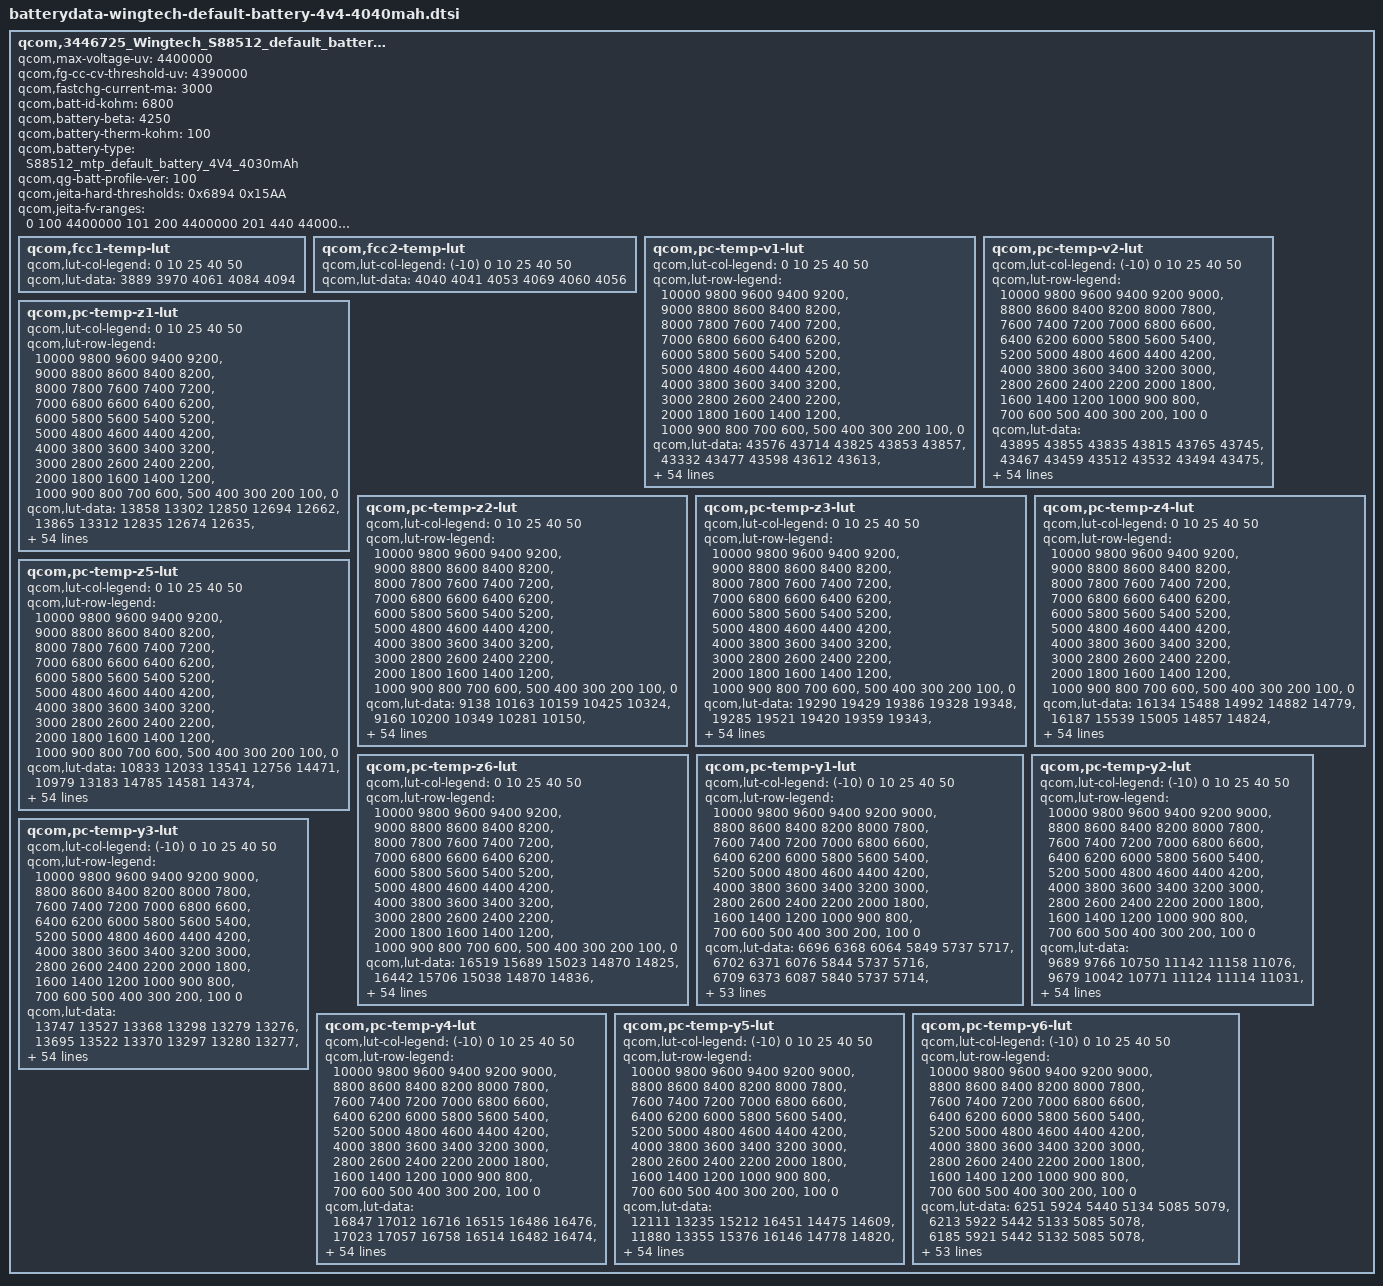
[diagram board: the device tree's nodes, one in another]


qcom,3446725_Wingtech_S88512_default_battery_4V4_4040mAh {
	/* 3446725_Wingtech_S88512_default_battery_4040mAh_averaged_MasterSlave_May16th2018 */
	qcom,max-voltage-uv = <4400000>;
	qcom,fg-cc-cv-threshold-uv = <4390000>;
	qcom,fastchg-current-ma = <3000>;
	qcom,batt-id-kohm = <6800>;
	qcom,battery-beta = <4250>;
	qcom,battery-therm-kohm = <100>;
	qcom,battery-type = "S88512_mtp_default_battery_4V4_4030mAh";
	qcom,qg-batt-profile-ver = <100>;
	/* COLD = 0 DegC, HOT = 60 DegC */
	qcom,jeita-hard-thresholds = <0x6894 0x15AA>;
        qcom,jeita-fv-ranges = <0   100  4400000
                                101 200  4400000
                                201 440  4400000
                                441 580  4100000>;
	qcom,fcc1-temp-lut {
		qcom,lut-col-legend = <0 10 25 40 50>;
		qcom,lut-data = <3889 3970 4061 4084 4094>;
	};

	qcom,fcc2-temp-lut {
		qcom,lut-col-legend = <(-10) 0 10 25 40 50>;
		qcom,lut-data = <4040 4041 4053 4069 4060 4056>;
	};

	qcom,pc-temp-v1-lut {
		qcom,lut-col-legend = <0 10 25 40 50>;
		qcom,lut-row-legend = <10000 9800 9600 9400 9200>,
			<9000 8800 8600 8400 8200>,
			<8000 7800 7600 7400 7200>,
			<7000 6800 6600 6400 6200>,
			<6000 5800 5600 5400 5200>,
			<5000 4800 4600 4400 4200>,
			<4000 3800 3600 3400 3200>,
			<3000 2800 2600 2400 2200>,
			<2000 1800 1600 1400 1200>,
			<1000 900 800 700 600>,
			<500 400 300 200 100>,
			<0>;
		qcom,lut-data = <43576 43714 43825 43853 43857>,
			<43332 43477 43598 43612 43613>,
			<43088 43215 43356 43378 43382>,
			<42842 42957 43107 43140 43149>,
			<42597 42714 42860 42899 42913>,
			<42363 42479 42619 42661 42678>,
			<42137 42254 42382 42425 42443>,
			<41920 42037 42148 42190 42209>,
			<41708 41823 41918 41958 41977>,
			<41506 41604 41694 41728 41746>,
			<41329 41394 41468 41499 41517>,
			<41183 41218 41256 41275 41293>,
			<41009 41069 41079 41067 41073>,
			<40713 40877 40922 40874 40860>,
			<40355 40551 40711 40671 40652>,
			<40111 40219 40387 40436 40450>,
			<39942 40031 40103 40206 40255>,
			<39804 39899 39958 40033 40073>,
			<39684 39779 39848 39888 39901>,
			<39579 39677 39718 39739 39736>,
			<39469 39565 39573 39588 39586>,
			<39357 39368 39405 39420 39426>,
			<39231 39089 39167 39195 39208>,
			<39061 38894 38922 38946 38957>,
			<38861 38779 38769 38774 38778>,
			<38720 38690 38658 38651 38654>,
			<38625 38615 38559 38545 38546>,
			<38553 38553 38464 38445 38443>,
			<38502 38494 38379 38355 38349>,
			<38464 38435 38304 38274 38264>,
			<38427 38382 38239 38201 38189>,
			<38391 38332 38182 38135 38121>,
			<38357 38286 38133 38079 38061>,
			<38321 38246 38090 38027 38005>,
			<38285 38214 38054 37982 37951>,
			<38265 38181 38020 37941 37900>,
			<38259 38150 37985 37896 37846>,
			<38254 38118 37950 37850 37792>,
			<38224 38068 37904 37792 37726>,
			<38131 37977 37825 37710 37639>,
			<38018 37865 37721 37607 37533>,
			<37885 37741 37605 37493 37417>,
			<37732 37596 37469 37360 37286>,
			<37558 37420 37311 37205 37132>,
			<37393 37294 37166 37063 36992>,
			<37277 37208 37071 36976 36917>,
			<37242 37173 37044 36953 36893>,
			<37211 37150 37031 36937 36874>,
			<37183 37124 37015 36920 36859>,
			<37137 37083 36972 36870 36798>,
			<36931 36862 36739 36621 36527>,
			<36489 36423 36306 36187 36086>,
			<35907 35842 35726 35612 35508>,
			<35118 35048 34934 34829 34714>,
			<33872 33805 33702 33622 33487>,
			<30000 30000 30000 30000 30000>;
	};

	qcom,pc-temp-v2-lut {
		qcom,lut-col-legend = <(-10) 0 10 25 40 50>;
		qcom,lut-row-legend = <10000 9800 9600 9400 9200 9000>,
			<8800 8600 8400 8200 8000 7800>,
			<7600 7400 7200 7000 6800 6600>,
			<6400 6200 6000 5800 5600 5400>,
			<5200 5000 4800 4600 4400 4200>,
			<4000 3800 3600 3400 3200 3000>,
			<2800 2600 2400 2200 2000 1800>,
			<1600 1400 1200 1000 900 800>,
			<700 600 500 400 300 200>,
			<100 0>;
		qcom,lut-data = <43895 43855 43835 43815 43765 43745>,
			<43467 43459 43512 43532 43494 43475>,
			<43086 43103 43210 43262 43232 43213>,
			<42755 42794 42934 43004 42980 42964>,
			<42462 42521 42681 42759 42738 42724>,
			<42213 42270 42434 42518 42499 42487>,
			<42013 42045 42189 42279 42261 42250>,
			<41826 41825 41950 42043 42025 42015>,
			<41589 41559 41720 41812 41794 41783>,
			<41318 41266 41497 41585 41566 41553>,
			<41146 41095 41287 41360 41340 41327>,
			<41074 41033 41095 41133 41117 41105>,
			<40990 40962 40901 40919 40901 40888>,
			<40663 40650 40688 40738 40701 40680>,
			<40078 40094 40461 40567 40508 40478>,
			<39713 39816 40218 40345 40308 40282>,
			<39513 39714 39943 40049 40095 40092>,
			<39337 39609 39718 39815 39900 39910>,
			<39144 39423 39584 39691 39740 39744>,
			<38958 39188 39471 39584 39590 39581>,
			<38787 38955 39296 39419 39411 39399>,
			<38625 38707 39049 39197 39206 39197>,
			<38493 38507 38826 38984 39004 38999>,
			<38393 38363 38647 38783 38800 38796>,
			<38311 38250 38492 38606 38615 38612>,
			<38239 38173 38363 38473 38480 38476>,
			<38177 38115 38252 38365 38371 38367>,
			<38118 38064 38152 38266 38273 38267>,
			<38062 38019 38057 38177 38183 38174>,
			<38010 37977 37979 38096 38101 38089>,
			<37958 37936 37929 38021 38027 38015>,
			<37909 37897 37892 37951 37957 37947>,
			<37859 37857 37856 37888 37895 37885>,
			<37809 37819 37823 37828 37841 37830>,
			<37757 37778 37792 37774 37781 37768>,
			<37702 37735 37762 37729 37700 37673>,
			<37641 37688 37730 37685 37611 37562>,
			<37577 37633 37688 37626 37529 37466>,
			<37509 37568 37631 37554 37450 37379>,
			<37433 37492 37558 37477 37372 37297>,
			<37347 37402 37453 37395 37300 37228>,
			<37250 37293 37327 37299 37213 37145>,
			<37140 37158 37185 37178 37092 37025>,
			<37043 37010 37031 37040 36956 36882>,
			<36960 36884 36889 36900 36825 36766>,
			<36882 36794 36819 36865 36795 36738>,
			<36846 36762 36796 36851 36784 36728>,
			<36808 36735 36770 36831 36771 36714>,
			<36755 36695 36727 36804 36746 36685>,
			<36663 36612 36636 36733 36667 36580>,
			<36452 36407 36397 36464 36362 36244>,
			<36057 35987 35923 35965 35876 35744>,
			<35472 35365 35266 35322 35246 35091>,
			<34618 34497 34367 34439 34382 34207>,
			<33256 33107 32959 33143 33095 32915>,
			<28698 28620 28473 28424 29170 28828>;
	};

	qcom,pc-temp-z1-lut {
		qcom,lut-col-legend = <0 10 25 40 50>;
		qcom,lut-row-legend = <10000 9800 9600 9400 9200>,
			<9000 8800 8600 8400 8200>,
			<8000 7800 7600 7400 7200>,
			<7000 6800 6600 6400 6200>,
			<6000 5800 5600 5400 5200>,
			<5000 4800 4600 4400 4200>,
			<4000 3800 3600 3400 3200>,
			<3000 2800 2600 2400 2200>,
			<2000 1800 1600 1400 1200>,
			<1000 900 800 700 600>,
			<500 400 300 200 100>,
			<0>;
		qcom,lut-data = <13858 13302 12850 12694 12662>,
			<13865 13312 12835 12674 12635>,
			<13865 13301 12817 12658 12624>,
			<13852 13289 12808 12649 12618>,
			<13835 13279 12801 12639 12614>,
			<13824 13268 12797 12633 12609>,
			<13814 13259 12794 12628 12604>,
			<13804 13250 12790 12624 12601>,
			<13794 13242 12784 12621 12599>,
			<13782 13236 12781 12619 12598>,
			<13767 13231 12785 12619 12597>,
			<13744 13222 12788 12620 12596>,
			<13718 13208 12785 12619 12596>,
			<13679 13192 12774 12618 12595>,
			<13636 13167 12763 12616 12595>,
			<13621 13148 12752 12611 12595>,
			<13617 13149 12745 12606 12596>,
			<13613 13161 12748 12607 12596>,
			<13605 13171 12755 12611 12597>,
			<13595 13179 12759 12614 12598>,
			<13596 13184 12764 12616 12599>,
			<13624 13185 12768 12618 12600>,
			<13647 13185 12771 12620 12602>,
			<13644 13185 12775 12623 12603>,
			<13633 13194 12779 12626 12606>,
			<13630 13204 12784 12628 12610>,
			<13635 13204 12788 12631 12614>,
			<13639 13201 12791 12635 12616>,
			<13640 13201 12794 12638 12619>,
			<13639 13204 12796 12643 12622>,
			<13640 13208 12799 12648 12626>,
			<13647 13213 12804 12652 12629>,
			<13656 13221 12823 12654 12632>,
			<13660 13227 12837 12656 12635>,
			<13667 13229 12832 12661 12639>,
			<13675 13232 12822 12666 12644>,
			<13690 13238 12822 12670 12648>,
			<13706 13250 12829 12674 12650>,
			<13718 13261 12834 12677 12653>,
			<13734 13274 12841 12680 12656>,
			<13749 13283 12847 12684 12658>,
			<13764 13284 12849 12686 12661>,
			<13776 13285 12850 12690 12664>,
			<13786 13288 12849 12692 12666>,
			<13790 13304 12851 12695 12667>,
			<13848 13297 12852 12697 12669>,
			<13809 13296 12855 12696 12669>,
			<13794 13305 12852 12700 12670>,
			<13812 13305 12859 12702 12672>,
			<13834 13304 12868 12708 12677>,
			<13816 13324 12867 12709 12683>,
			<13844 13334 12879 12714 12687>,
			<13854 13360 12885 12724 12694>,
			<13860 13371 12899 12734 12704>,
			<13860 13371 12899 12734 12704>,
			<13860 13371 12899 12734 12704>;
	};

	qcom,pc-temp-z2-lut {
		qcom,lut-col-legend = <0 10 25 40 50>;
		qcom,lut-row-legend = <10000 9800 9600 9400 9200>,
			<9000 8800 8600 8400 8200>,
			<8000 7800 7600 7400 7200>,
			<7000 6800 6600 6400 6200>,
			<6000 5800 5600 5400 5200>,
			<5000 4800 4600 4400 4200>,
			<4000 3800 3600 3400 3200>,
			<3000 2800 2600 2400 2200>,
			<2000 1800 1600 1400 1200>,
			<1000 900 800 700 600>,
			<500 400 300 200 100>,
			<0>;
		qcom,lut-data = <9138 10163 10159 10425 10324>,
			<9160 10200 10349 10281 10150>,
			<9213 10199 10329 10271 10230>,
			<9374 10193 10326 10277 10202>,
			<9581 10177 10320 10282 10158>,
			<9693 10154 10306 10271 10136>,
			<9871 10140 10290 10248 10114>,
			<9964 10128 10283 10222 10103>,
			<9958 10122 10276 10188 10104>,
			<9949 10118 10273 10166 10107>,
			<9925 10116 10269 10175 10106>,
			<9858 10121 10266 10191 10104>,
			<9816 10138 10279 10189 10106>,
			<9851 10153 10311 10173 10113>,
			<9914 10161 10321 10170 10121>,
			<9942 10168 10317 10214 10127>,
			<9954 10175 10311 10260 10136>,
			<9967 10182 10305 10245 10146>,
			<9990 10190 10298 10196 10159>,
			<10020 10206 10304 10183 10173>,
			<10042 10222 10341 10219 10191>,
			<10061 10229 10375 10276 10218>,
			<10073 10233 10394 10371 10315>,
			<10078 10235 10406 10480 10477>,
			<10081 10232 10407 10495 10501>,
			<10086 10228 10404 10455 10362>,
			<10099 10231 10398 10402 10234>,
			<10114 10237 10381 10319 10162>,
			<10124 10243 10359 10241 10103>,
			<10131 10249 10340 10226 10086>,
			<10141 10255 10321 10220 10075>,
			<10152 10261 10318 10219 10075>,
			<10165 10269 10335 10221 10085>,
			<10179 10277 10356 10224 10099>,
			<10195 10285 10375 10247 10129>,
			<10198 10293 10394 10295 10182>,
			<10129 10303 10412 10330 10228>,
			<10052 10314 10428 10355 10272>,
			<10126 10326 10447 10380 10308>,
			<10404 10345 10475 10415 10338>,
			<10543 10358 10498 10445 10360>,
			<10533 10361 10499 10451 10357>,
			<10521 10363 10498 10443 10337>,
			<10609 10379 10500 10433 10335>,
			<10406 20672 10522 10422 10336>,
			<10239 34190 10584 10395 10322>,
			<10252 37305 10581 10421 10324>,
			<10194 44657 10596 10434 10338>,
			<10183 40458 10602 10469 10409>,
			<10093 37138 10665 10531 10468>,
			<10033 35569 10685 10416 10278>,
			<9977 31869 10658 10323 10179>,
			<9848 31593 10602 10277 10147>,
			<9662 25080 10589 10238 10089>,
			<9662 25080 10589 10238 10089>,
			<9662 25080 10589 10238 10089>;
	};

	qcom,pc-temp-z3-lut {
		qcom,lut-col-legend = <0 10 25 40 50>;
		qcom,lut-row-legend = <10000 9800 9600 9400 9200>,
			<9000 8800 8600 8400 8200>,
			<8000 7800 7600 7400 7200>,
			<7000 6800 6600 6400 6200>,
			<6000 5800 5600 5400 5200>,
			<5000 4800 4600 4400 4200>,
			<4000 3800 3600 3400 3200>,
			<3000 2800 2600 2400 2200>,
			<2000 1800 1600 1400 1200>,
			<1000 900 800 700 600>,
			<500 400 300 200 100>,
			<0>;
		qcom,lut-data = <19290 19429 19386 19328 19348>,
			<19285 19521 19420 19359 19343>,
			<19284 19599 19455 19396 19376>,
			<19388 19640 19471 19406 19384>,
			<19543 19655 19477 19412 19389>,
			<19612 19663 19477 19412 19390>,
			<19765 19662 19476 19411 19391>,
			<19852 19656 19476 19410 19390>,
			<19853 19652 19475 19407 19390>,
			<19854 19655 19474 19405 19389>,
			<19798 19657 19474 19403 19388>,
			<19486 19647 19473 19401 19385>,
			<19266 19610 19464 19398 19383>,
			<19461 19594 19445 19390 19381>,
			<19803 19609 19440 19386 19379>,
			<19884 19625 19454 19393 19378>,
			<19858 19623 19465 19401 19376>,
			<19827 19610 19459 19396 19374>,
			<19803 19599 19448 19381 19371>,
			<19781 19591 19441 19374 19367>,
			<19775 19586 19435 19371 19360>,
			<19773 19591 19433 19370 19354>,
			<19772 19605 19440 19378 19362>,
			<19778 19610 19448 19394 19383>,
			<19793 19602 19448 19403 19392>,
			<19797 19594 19445 19407 19395>,
			<19791 19594 19445 19412 19397>,
			<19782 19595 19464 19418 19400>,
			<19773 19596 19483 19423 19404>,
			<19763 19600 19482 19422 19403>,
			<19753 19603 19479 19417 19395>,
			<19745 19603 19474 19411 19388>,
			<19736 19601 19468 19406 19383>,
			<19730 19599 19461 19400 19377>,
			<19725 19595 19456 19394 19371>,
			<19709 19590 19452 19388 19366>,
			<19510 19585 19449 19384 19363>,
			<19287 19581 19446 19381 19362>,
			<19261 19576 19443 19380 19362>,
			<19260 19571 19440 19381 19364>,
			<19260 19566 19437 19382 19368>,
			<19260 19562 19434 19381 19368>,
			<19260 19558 19432 19379 19366>,
			<19259 19551 19428 19379 19367>,
			<19260 19420 19416 19376 19369>,
			<19260 19256 19400 19363 19351>,
			<19260 19256 19401 19356 19346>,
			<19260 19256 19387 19351 19342>,
			<19260 19256 19381 19348 19329>,
			<19261 19256 19378 19344 19328>,
			<19261 19256 19376 19364 19356>,
			<19262 19256 19370 19366 19357>,
			<19263 19256 19370 19367 19359>,
			<19265 19256 19364 19368 19362>,
			<19265 19256 19364 19368 19362>,
			<19265 19256 19364 19368 19362>;
	};

	qcom,pc-temp-z4-lut {
		qcom,lut-col-legend = <0 10 25 40 50>;
		qcom,lut-row-legend = <10000 9800 9600 9400 9200>,
			<9000 8800 8600 8400 8200>,
			<8000 7800 7600 7400 7200>,
			<7000 6800 6600 6400 6200>,
			<6000 5800 5600 5400 5200>,
			<5000 4800 4600 4400 4200>,
			<4000 3800 3600 3400 3200>,
			<3000 2800 2600 2400 2200>,
			<2000 1800 1600 1400 1200>,
			<1000 900 800 700 600>,
			<500 400 300 200 100>,
			<0>;
		qcom,lut-data = <16134 15488 14992 14882 14779>,
			<16187 15539 15005 14857 14824>,
			<16194 15439 15044 14893 14848>,
			<16048 15326 14986 14869 14836>,
			<15791 15215 14926 14835 14815>,
			<15590 15106 14887 14813 14798>,
			<15349 15029 14854 14795 14783>,
			<15181 14968 14827 14780 14769>,
			<15094 14922 14805 14767 14755>,
			<15034 14888 14787 14756 14743>,
			<15066 14860 14774 14745 14733>,
			<15304 14829 14761 14735 14725>,
			<15473 14795 14743 14726 14718>,
			<15307 14784 14724 14716 14712>,
			<15007 14809 14720 14712 14707>,
			<14912 14838 14743 14714 14703>,
			<14898 14832 14761 14716 14699>,
			<14885 14802 14740 14711 14693>,
			<14861 14773 14702 14697 14687>,
			<14831 14743 14695 14692 14685>,
			<14807 14722 14699 14692 14686>,
			<14784 14757 14708 14692 14687>,
			<14772 14858 14766 14726 14712>,
			<14797 14900 14836 14787 14767>,
			<14856 14903 14842 14798 14780>,
			<14881 14905 14835 14784 14767>,
			<14886 14896 14824 14767 14751>,
			<14888 14870 14790 14746 14734>,
			<14882 14847 14758 14726 14716>,
			<14861 14826 14747 14717 14709>,
			<14842 14809 14741 14712 14705>,
			<14827 14798 14738 14708 14702>,
			<14812 14790 14736 14705 14697>,
			<14798 14784 14735 14704 14694>,
			<14784 14780 14733 14704 14694>,
			<14786 14776 14732 14705 14696>,
			<14975 14771 14731 14705 14697>,
			<15192 14766 14729 14706 14698>,
			<15213 14762 14728 14706 14698>,
			<15203 14761 14728 14707 14699>,
			<15193 14759 14728 14708 14700>,
			<15185 14750 14723 14704 14698>,
			<15173 14737 14710 14694 14691>,
			<15148 14723 14705 14693 14690>,
			<15056 14807 14696 14689 14687>,
			<15005 14923 14671 14667 14665>,
			<14995 14918 14660 14665 14661>,
			<14988 14909 14661 14654 14649>,
			<14983 14901 14657 14639 14640>,
			<14976 14897 14657 14639 14636>,
			<14986 14909 14675 14646 14643>,
			<15008 14918 14689 14652 14653>,
			<15016 14920 14690 14653 14653>,
			<15029 14924 14699 14654 14653>,
			<15029 14924 14699 14654 14653>,
			<15029 14924 14699 14654 14653>;
	};

	qcom,pc-temp-z5-lut {
		qcom,lut-col-legend = <0 10 25 40 50>;
		qcom,lut-row-legend = <10000 9800 9600 9400 9200>,
			<9000 8800 8600 8400 8200>,
			<8000 7800 7600 7400 7200>,
			<7000 6800 6600 6400 6200>,
			<6000 5800 5600 5400 5200>,
			<5000 4800 4600 4400 4200>,
			<4000 3800 3600 3400 3200>,
			<3000 2800 2600 2400 2200>,
			<2000 1800 1600 1400 1200>,
			<1000 900 800 700 600>,
			<500 400 300 200 100>,
			<0>;
		qcom,lut-data = <10833 12033 13541 12756 14471>,
			<10979 13183 14785 14581 14374>,
			<11111 14528 15669 16585 16813>,
			<11857 15766 16527 17255 17466>,
			<12960 16845 17196 17916 18063>,
			<13629 17791 17553 18145 18312>,
			<14992 18479 17839 18291 18443>,
			<16124 18975 18196 18330 18607>,
			<17006 19687 18607 18334 18847>,
			<17830 21581 19094 18341 19142>,
			<17304 23397 19884 18767 19512>,
			<13451 22968 20493 19417 19959>,
			<10725 20882 20312 19482 20396>,
			<16383 20034 19776 19296 20816>,
			<26306 23762 19751 19246 21297>,
			<28422 27975 21304 21663 21950>,
			<25810 27626 23022 24476 22690>,
			<23553 25411 23905 23957 23463>,
			<23157 24534 24611 21925 24372>,
			<22933 26191 25354 21278 24636>,
			<23107 29175 26309 21891 23406>,
			<25522 34046 26760 22480 22198>,
			<29397 41155 26391 22741 22610>,
			<36017 43199 25572 22966 23636>,
			<44929 36324 23862 22441 23578>,
			<47492 28984 20630 20499 21117>,
			<44754 27387 19488 19440 19433>,
			<41087 26577 22283 20948 21086>,
			<38273 26507 26031 23405 23697>,
			<35651 28161 28420 25029 24547>,
			<34248 30536 30414 26356 24968>,
			<33511 32887 31787 27508 25107>,
			<33113 35389 32786 28713 25580>,
			<33293 36740 33486 29426 26229>,
			<33895 37547 34003 29351 26637>,
			<33816 37991 34369 29115 26952>,
			<23827 37942 34273 28841 27004>,
			<12336 37631 33429 28292 26775>,
			<11128 37207 32415 27705 26588>,
			<11158 36246 30871 27094 26921>,
			<11173 35250 29300 26486 27391>,
			<11161 34602 28730 26080 27015>,
			<11152 34032 28385 25773 25942>,
			<11182 33493 26890 25534 26538>,
			<11418 23782 25282 24675 27366>,
			<11549 11485 25564 23342 22743>,
			<11494 11465 27321 21179 20856>,
			<11497 11387 22905 21547 21542>,
			<11484 11400 21545 23906 20574>,
			<11502 11418 21359 22401 20654>,
			<11519 11401 18583 24053 25830>,
			<11415 11340 16556 22187 22912>,
			<11355 11281 16283 21256 21311>,
			<11255 11219 15399 19991 19943>,
			<11255 11219 15399 19991 19943>,
			<11255 11219 15399 19991 19943>;
	};

	qcom,pc-temp-z6-lut {
		qcom,lut-col-legend = <0 10 25 40 50>;
		qcom,lut-row-legend = <10000 9800 9600 9400 9200>,
			<9000 8800 8600 8400 8200>,
			<8000 7800 7600 7400 7200>,
			<7000 6800 6600 6400 6200>,
			<6000 5800 5600 5400 5200>,
			<5000 4800 4600 4400 4200>,
			<4000 3800 3600 3400 3200>,
			<3000 2800 2600 2400 2200>,
			<2000 1800 1600 1400 1200>,
			<1000 900 800 700 600>,
			<500 400 300 200 100>,
			<0>;
		qcom,lut-data = <16519 15689 15023 14870 14825>,
			<16442 15706 15038 14870 14836>,
			<16359 15661 15062 14900 14862>,
			<16262 15605 15039 14892 14858>,
			<16164 15538 15013 14880 14851>,
			<16083 15465 14992 14870 14845>,
			<16007 15410 14973 14860 14838>,
			<15939 15363 14957 14852 14831>,
			<15883 15327 14945 14844 14825>,
			<15830 15302 14935 14837 14820>,
			<15765 15280 14929 14832 14814>,
			<15679 15244 14922 14827 14809>,
			<15631 15198 14907 14820 14804>,
			<15631 15179 14885 14810 14800>,
			<15632 15183 14880 14806 14797>,
			<15628 15188 14893 14810 14794>,
			<15596 15183 14903 14813 14791>,
			<15558 15163 14892 14809 14788>,
			<15526 15148 14873 14795 14784>,
			<15497 15138 14869 14790 14780>,
			<15487 15132 14870 14789 14777>,
			<15483 15151 14872 14789 14774>,
			<15482 15204 14901 14808 14790>,
			<15497 15225 14937 14845 14826>,
			<15532 15224 14941 14852 14835>,
			<15545 15223 14938 14850 14832>,
			<15546 15220 14935 14847 14828>,
			<15545 15211 14932 14843 14824>,
			<15540 15205 14929 14838 14820>,
			<15528 15200 14926 14833 14815>,
			<15517 15197 14922 14829 14810>,
			<15508 15194 14919 14825 14806>,
			<15501 15191 14916 14822 14801>,
			<15496 15190 14914 14819 14797>,
			<15493 15189 14912 14816 14794>,
			<15489 15189 14911 14813 14792>,
			<15480 15189 14910 14812 14791>,
			<15471 15189 14909 14811 14791>,
			<15473 15190 14909 14811 14791>,
			<15484 15194 14910 14812 14793>,
			<15495 15197 14911 14814 14796>,
			<15505 15197 14909 14813 14795>,
			<15513 15197 14904 14808 14791>,
			<15520 15198 14902 14808 14792>,
			<15506 15183 14895 14806 14792>,
			<15493 15160 14878 14791 14774>,
			<15488 15158 14875 14786 14769>,
			<15489 15155 14869 14778 14762>,
			<15490 15156 14865 14770 14752>,
			<15495 15161 14866 14770 14750>,
			<15511 15174 14877 14785 14769>,
			<15528 15186 14883 14791 14776>,
			<15548 15194 14887 14794 14780>,
			<15576 15212 14894 14798 14784>,
			<15576 15212 14894 14798 14784>,
			<15576 15212 14894 14798 14784>;
	};

	qcom,pc-temp-y1-lut {
		qcom,lut-col-legend = <(-10) 0 10 25 40 50>;
		qcom,lut-row-legend = <10000 9800 9600 9400 9200 9000>,
			<8800 8600 8400 8200 8000 7800>,
			<7600 7400 7200 7000 6800 6600>,
			<6400 6200 6000 5800 5600 5400>,
			<5200 5000 4800 4600 4400 4200>,
			<4000 3800 3600 3400 3200 3000>,
			<2800 2600 2400 2200 2000 1800>,
			<1600 1400 1200 1000 900 800>,
			<700 600 500 400 300 200>,
			<100 0>;
		qcom,lut-data = <6696 6368 6064 5849 5737 5717>,
			<6702 6371 6076 5844 5737 5716>,
			<6709 6373 6087 5840 5737 5714>,
			<6715 6374 6095 5836 5737 5713>,
			<6720 6374 6101 5834 5736 5712>,
			<6721 6374 6102 5833 5736 5711>,
			<6721 6373 6100 5834 5736 5711>,
			<6719 6372 6096 5835 5735 5711>,
			<6714 6372 6091 5834 5734 5711>,
			<6702 6371 6085 5830 5732 5709>,
			<6698 6371 6083 5827 5731 5709>,
			<6702 6372 6086 5825 5730 5709>,
			<6708 6374 6089 5824 5730 5710>,
			<6716 6381 6089 5823 5727 5709>,
			<6728 6393 6089 5823 5724 5708>,
			<6740 6395 6090 5824 5724 5707>,
			<6756 6389 6093 5829 5729 5709>,
			<6764 6383 6096 5833 5733 5711>,
			<6756 6460 6097 5836 5731 5711>,
			<6741 6593 6097 5839 5729 5711>,
			<6739 6593 6099 5838 5729 5711>,
			<6745 6458 6101 5834 5731 5710>,
			<6748 6378 6102 5832 5733 5710>,
			<6738 6382 6100 5836 5735 5712>,
			<6725 6387 6098 5840 5738 5714>,
			<6720 6389 6099 5841 5740 5716>,
			<6718 6391 6103 5842 5743 5718>,
			<6717 6391 6104 5843 5745 5720>,
			<6715 6387 6101 5844 5745 5722>,
			<6715 6382 6099 5846 5746 5724>,
			<6720 6382 6098 5848 5747 5726>,
			<6730 6386 6095 5850 5748 5728>,
			<6733 6387 6095 5851 5750 5730>,
			<6727 6381 6102 5852 5755 5733>,
			<6719 6377 6106 5853 5758 5735>,
			<6707 6383 6101 5856 5759 5736>,
			<6693 6395 6094 5858 5759 5737>,
			<6692 6395 6095 5857 5759 5739>,
			<6701 6382 6105 5855 5760 5741>,
			<6708 6370 6110 5854 5761 5742>,
			<6705 6361 6102 5857 5761 5742>,
			<6703 6355 6095 5857 5761 5741>,
			<6717 6376 6095 5853 5762 5744>,
			<6723 6378 6095 5858 5767 5747>,
			<6771 6404 6110 5859 5769 5748>,
			<6763 6413 6115 5863 5773 5754>,
			<6772 6411 6111 5866 5774 5753>,
			<6765 6413 6116 5868 5772 5751>,
			<6776 6416 6124 5866 5771 5751>,
			<6793 6412 6118 5866 5773 5752>,
			<6791 6424 6123 5868 5777 5754>,
			<6803 6432 6129 5872 5777 5758>,
			<6814 6441 6144 5880 5783 5762>,
			<6830 6462 6162 5913 5794 5772>,
			<6830 6462 6162 5913 5794 5772>,
			<6830 6462 6162 5913 5794 5772>;
	};

	qcom,pc-temp-y2-lut {
		qcom,lut-col-legend = <(-10) 0 10 25 40 50>;
		qcom,lut-row-legend = <10000 9800 9600 9400 9200 9000>,
			<8800 8600 8400 8200 8000 7800>,
			<7600 7400 7200 7000 6800 6600>,
			<6400 6200 6000 5800 5600 5400>,
			<5200 5000 4800 4600 4400 4200>,
			<4000 3800 3600 3400 3200 3000>,
			<2800 2600 2400 2200 2000 1800>,
			<1600 1400 1200 1000 900 800>,
			<700 600 500 400 300 200>,
			<100 0>;
		qcom,lut-data = <9689 9766 10750 11142 11158 11076>,
			<9679 10042 10771 11124 11114 11031>,
			<9674 10234 10783 11099 11061 10981>,
			<9675 10356 10786 11072 11007 10933>,
			<9679 10418 10785 11049 10964 10895>,
			<9693 10432 10781 11033 10940 10874>,
			<9929 10347 10766 11022 10931 10865>,
			<10202 10248 10744 11011 10923 10862>,
			<10124 10341 10721 10994 10897 10861>,
			<9817 10645 10696 10969 10850 10858>,
			<9708 10751 10689 10953 10830 10849>,
			<9864 10562 10692 10936 10835 10806>,
			<10010 10383 10700 10920 10840 10769>,
			<9927 10424 10758 10895 10835 10768>,
			<9733 10549 10864 10865 10831 10774>,
			<9676 10649 10891 10867 10827 10773>,
			<9673 10737 10888 10914 10821 10766>,
			<9671 10783 10887 10967 10825 10762>,
			<9669 10773 10935 11019 10871 10766>,
			<9668 10742 11005 11065 10941 10776>,
			<9667 10589 11006 11086 10988 10804>,
			<9667 10012 10962 11100 11028 10874>,
			<9666 9685 10940 11105 11041 10926>,
			<9665 9686 10986 11114 11014 10965>,
			<9665 9687 11047 11130 10985 10998>,
			<9664 9686 11073 11161 11003 11015>,
			<9663 9681 11089 11212 11064 11037>,
			<9662 9677 11098 11236 11114 11063>,
			<9662 9674 11104 11246 11159 11102>,
			<9661 9671 11105 11252 11189 11132>,
			<9660 9669 11064 11255 11195 11141>,
			<9660 9667 10976 11258 11194 11145>,
			<9660 9665 10938 11261 11201 11148>,
			<9659 9663 10927 11267 11226 11161>,
			<9659 9662 10909 11269 11240 11168>,
			<9658 9661 10858 11263 11217 11136>,
			<9658 9660 10783 11254 11182 11090>,
			<9658 9659 10723 11246 11175 11078>,
			<9658 9658 10673 11232 11186 11075>,
			<9657 9657 10586 11212 11184 11069>,
			<9657 9657 10269 11163 11124 11049>,
			<9657 9656 9961 11133 11093 11031>,
			<9657 9656 9779 11121 11108 11018>,
			<9656 9656 9721 11108 11086 11030>,
			<9656 9655 9718 11072 11119 10992>,
			<9655 9655 9693 11021 10996 10872>,
			<9655 9655 9686 10997 10953 10885>,
			<9655 9655 9679 10968 10951 10858>,
			<9655 9654 9674 10947 10945 10786>,
			<9654 9654 9670 10943 10980 10827>,
			<9654 9654 9667 10913 10916 10800>,
			<9653 9654 9664 10833 10833 10721>,
			<9652 9653 9660 10774 10810 10677>,
			<9651 9652 9658 10727 10686 10560>,
			<9651 9652 9658 10727 10686 10560>,
			<9651 9652 9658 10727 10686 10560>;
	};

	qcom,pc-temp-y3-lut {
		qcom,lut-col-legend = <(-10) 0 10 25 40 50>;
		qcom,lut-row-legend = <10000 9800 9600 9400 9200 9000>,
			<8800 8600 8400 8200 8000 7800>,
			<7600 7400 7200 7000 6800 6600>,
			<6400 6200 6000 5800 5600 5400>,
			<5200 5000 4800 4600 4400 4200>,
			<4000 3800 3600 3400 3200 3000>,
			<2800 2600 2400 2200 2000 1800>,
			<1600 1400 1200 1000 900 800>,
			<700 600 500 400 300 200>,
			<100 0>;
		qcom,lut-data = <13747 13527 13368 13298 13279 13276>,
			<13695 13522 13370 13297 13280 13277>,
			<13653 13519 13371 13297 13281 13278>,
			<13622 13519 13373 13297 13282 13279>,
			<13603 13521 13374 13297 13282 13280>,
			<13598 13524 13376 13296 13283 13280>,
			<13613 13537 13377 13296 13283 13281>,
			<13631 13550 13378 13296 13283 13281>,
			<13609 13528 13378 13296 13284 13281>,
			<13537 13459 13378 13297 13285 13282>,
			<13505 13431 13379 13299 13286 13282>,
			<13512 13433 13387 13302 13288 13282>,
			<13521 13435 13395 13305 13290 13282>,
			<13519 13432 13393 13311 13290 13283>,
			<13512 13425 13387 13316 13290 13286>,
			<13505 13424 13379 13316 13291 13287>,
			<13493 13427 13365 13310 13291 13287>,
			<13485 13429 13357 13307 13291 13287>,
			<13489 13420 13358 13310 13293 13288>,
			<13495 13401 13359 13313 13295 13289>,
			<13494 13385 13357 13313 13295 13289>,
			<13485 13371 13346 13309 13294 13289>,
			<13480 13358 13337 13305 13293 13288>,
			<13487 13341 13332 13299 13288 13284>,
			<13501 13328 13329 13295 13284 13279>,
			<13518 13330 13326 13294 13282 13278>,
			<13544 13343 13324 13293 13282 13277>,
			<13571 13360 13322 13293 13281 13277>,
			<13597 13383 13320 13293 13283 13277>,
			<13625 13411 13318 13294 13283 13277>,
			<13657 13438 13299 13293 13283 13278>,
			<13692 13466 13267 13293 13283 13279>,
			<13731 13500 13263 13292 13282 13279>,
			<13775 13542 13295 13292 13283 13280>,
			<13819 13589 13321 13292 13283 13281>,
			<13862 13638 13329 13293 13282 13279>,
			<13906 13689 13334 13294 13280 13277>,
			<13955 13748 13339 13294 13280 13277>,
			<14012 13814 13346 13293 13281 13277>,
			<14072 13885 13351 13293 13281 13277>,
			<14135 13956 13354 13294 13284 13280>,
			<14203 14033 13359 13295 13285 13283>,
			<14274 14129 13377 13298 13285 13283>,
			<14385 14239 13397 13298 13285 13280>,
			<14442 14280 13392 13294 13281 13279>,
			<14596 14423 13425 13300 13285 13283>,
			<14692 14513 13447 13303 13288 13287>,
			<14800 14610 13472 13305 13292 13289>,
			<14930 14704 13503 13312 13295 13290>,
			<15077 14796 13545 13316 13295 13289>,
			<15236 14895 13590 13313 13289 13286>,
			<15436 15000 13645 13313 13291 13288>,
			<15900 15164 13767 13321 13297 13291>,
			<17006 15564 13957 13331 13302 13298>,
			<17006 15564 13957 13331 13302 13298>,
			<17006 15564 13957 13331 13302 13298>;
	};

	qcom,pc-temp-y4-lut {
		qcom,lut-col-legend = <(-10) 0 10 25 40 50>;
		qcom,lut-row-legend = <10000 9800 9600 9400 9200 9000>,
			<8800 8600 8400 8200 8000 7800>,
			<7600 7400 7200 7000 6800 6600>,
			<6400 6200 6000 5800 5600 5400>,
			<5200 5000 4800 4600 4400 4200>,
			<4000 3800 3600 3400 3200 3000>,
			<2800 2600 2400 2200 2000 1800>,
			<1600 1400 1200 1000 900 800>,
			<700 600 500 400 300 200>,
			<100 0>;
		qcom,lut-data = <16847 17012 16716 16515 16486 16476>,
			<17023 17057 16758 16514 16482 16474>,
			<17152 17117 16800 16514 16479 16472>,
			<17238 17178 16837 16514 16477 16470>,
			<17285 17227 16862 16514 16476 16468>,
			<17297 17252 16869 16515 16475 16468>,
			<17244 17259 16858 16517 16476 16468>,
			<17181 17266 16846 16519 16477 16469>,
			<17243 17296 16845 16522 16478 16469>,
			<17478 17379 16846 16525 16479 16470>,
			<17681 17496 16847 16527 16480 16471>,
			<17855 17743 16861 16528 16481 16475>,
			<17962 17935 16883 16530 16483 16478>,
			<17731 17696 16921 16544 16492 16479>,
			<17210 17153 16970 16567 16508 16480>,
			<17057 17015 16970 16572 16517 16483>,
			<17054 17129 16893 16572 16520 16489>,
			<17050 17215 16841 16572 16525 16497>,
			<17012 17173 16894 16614 16539 16510>,
			<16942 17077 16974 16670 16556 16525>,
			<16890 16978 16957 16669 16562 16533>,
			<16845 16860 16826 16640 16566 16538>,
			<16822 16782 16716 16604 16566 16539>,
			<16818 16747 16654 16546 16524 16509>,
			<16816 16727 16609 16500 16479 16474>,
			<16813 16724 16586 16494 16474 16471>,
			<16809 16725 16571 16491 16473 16470>,
			<16808 16726 16554 16491 16473 16470>,
			<16812 16725 16529 16493 16475 16472>,
			<16818 16725 16512 16496 16477 16474>,
			<16823 16730 16555 16500 16482 16478>,
			<16831 16745 16643 16504 16490 16485>,
			<16839 16760 16659 16504 16499 16493>,
			<16847 16773 16618 16500 16510 16506>,
			<16855 16786 16590 16498 16516 16513>,
			<16866 16801 16610 16499 16499 16496>,
			<16879 16817 16647 16500 16475 16471>,
			<16890 16830 16673 16498 16467 16463>,
			<16899 16842 16694 16492 16464 16461>,
			<16904 16855 16709 16491 16463 16460>,
			<16897 16878 16716 16501 16476 16476>,
			<16891 16892 16723 16510 16483 16485>,
			<16892 16855 16734 16515 16480 16481>,
			<16894 16835 16744 16521 16478 16471>,
			<16883 16798 16719 16499 16459 16451>,
			<16914 16820 16750 16519 16474 16467>,
			<16937 16846 16773 16530 16488 16489>,
			<16976 16875 16802 16551 16514 16527>,
			<17028 16924 16840 16584 16556 16576>,
			<17078 16981 16893 16623 16581 16567>,
			<17086 17009 16915 16591 16504 16490>,
			<17067 17001 16906 16579 16499 16487>,
			<17127 16998 16935 16622 16519 16497>,
			<17509 17121 17008 16693 16570 16554>,
			<17509 17121 17008 16693 16570 16554>,
			<17509 17121 17008 16693 16570 16554>;
	};

	qcom,pc-temp-y5-lut {
		qcom,lut-col-legend = <(-10) 0 10 25 40 50>;
		qcom,lut-row-legend = <10000 9800 9600 9400 9200 9000>,
			<8800 8600 8400 8200 8000 7800>,
			<7600 7400 7200 7000 6800 6600>,
			<6400 6200 6000 5800 5600 5400>,
			<5200 5000 4800 4600 4400 4200>,
			<4000 3800 3600 3400 3200 3000>,
			<2800 2600 2400 2200 2000 1800>,
			<1600 1400 1200 1000 900 800>,
			<700 600 500 400 300 200>,
			<100 0>;
		qcom,lut-data = <12111 13235 15212 16451 14475 14609>,
			<11880 13355 15376 16146 14778 14820>,
			<11773 13613 15587 15806 14896 15120>,
			<11779 13988 15794 15451 14898 15421>,
			<11886 14454 15947 15099 14854 15635>,
			<12120 14996 15996 14764 14826 15671>,
			<14472 15840 15964 14369 14635 15512>,
			<17124 16532 15926 14055 14424 15348>,
			<16166 15597 15928 13951 14536 15264>,
			<12587 12646 15942 13875 14866 15068>,
			<11342 11638 15840 13900 14995 14888>,
			<13746 13813 14684 14387 15235 14477>,
			<16024 15870 13666 14844 15393 14158>,
			<15196 15399 14472 14964 15052 14516>,
			<13135 14190 16155 15032 14441 15243>,
			<12453 14041 16397 14881 14065 15352>,
			<12405 15647 15208 14165 13798 14894>,
			<12437 17074 14398 13742 13685 14486>,
			<12606 17481 15389 13912 13794 14268>,
			<12825 17725 17042 14316 14070 14131>,
			<12724 17391 17733 15394 14861 14546>,
			<11962 15367 18090 17719 16760 15976>,
			<11396 13495 18301 18637 17599 16655>,
			<11224 12267 18407 18218 17536 16416>,
			<11126 11429 18503 17740 17449 16108>,
			<11147 11332 18734 17570 17275 15939>,
			<11276 11327 19088 17465 16882 15717>,
			<11339 11341 19170 17528 16787 15612>,
			<11370 11524 18557 17912 17351 15457>,
			<11421 11745 17495 18205 17822 15347>,
			<11484 11821 15236 18232 17594 15522>,
			<11576 11864 12124 18251 17202 15951>,
			<11683 11945 11654 18359 17266 16473>,
			<11853 12141 13496 18731 18081 17303>,
			<11983 12355 15062 18965 18579 17870>,
			<11980 12534 15503 19054 18199 18053>,
			<11940 12688 15794 19117 17690 18143>,
			<11959 12744 16126 18957 17659 18008>,
			<12033 12768 16516 18403 17798 17603>,
			<12105 12777 16660 17819 18018 17466>,
			<12165 12479 15746 16965 18721 19055>,
			<12191 12187 14618 16772 18995 20157>,
			<11725 12245 13731 17290 18555 20163>,
			<11598 12094 13178 16949 18594 17966>,
			<11556 12284 12692 16609 16931 17800>,
			<11506 12083 12688 16886 16177 16719>,
			<11585 12008 12774 16488 16381 16773>,
			<11648 12116 12720 15743 16875 15876>,
			<11712 12088 12610 16116 16260 15029>,
			<11945 12181 12735 16341 15606 14774>,
			<11972 12357 13095 16997 16390 16883>,
			<11823 12224 12795 17382 17070 17032>,
			<11483 12033 12468 17450 19010 17302>,
			<10671 11584 12439 17807 19619 19967>,
			<10671 11584 12439 17807 19619 19967>,
			<10671 11584 12439 17807 19619 19967>;
	};

	qcom,pc-temp-y6-lut {
		qcom,lut-col-legend = <(-10) 0 10 25 40 50>;
		qcom,lut-row-legend = <10000 9800 9600 9400 9200 9000>,
			<8800 8600 8400 8200 8000 7800>,
			<7600 7400 7200 7000 6800 6600>,
			<6400 6200 6000 5800 5600 5400>,
			<5200 5000 4800 4600 4400 4200>,
			<4000 3800 3600 3400 3200 3000>,
			<2800 2600 2400 2200 2000 1800>,
			<1600 1400 1200 1000 900 800>,
			<700 600 500 400 300 200>,
			<100 0>;
		qcom,lut-data = <6251 5924 5440 5134 5085 5079>,
			<6213 5922 5442 5133 5085 5078>,
			<6185 5921 5442 5132 5085 5078>,
			<6166 5919 5442 5132 5085 5078>,
			<6156 5917 5442 5131 5085 5078>,
			<6153 5915 5440 5130 5085 5078>,
			<6165 5914 5433 5130 5085 5078>,
			<6178 5912 5423 5130 5086 5079>,
			<6174 5901 5416 5130 5086 5079>,
			<6159 5876 5411 5131 5087 5080>,
			<6157 5870 5410 5132 5089 5080>,
			<6222 5938 5415 5134 5090 5081>,
			<6284 6003 5420 5137 5091 5082>,
			<6216 5940 5426 5144 5095 5083>,
			<6061 5795 5433 5153 5099 5085>,
			<6018 5759 5430 5154 5101 5087>,
			<6023 5800 5403 5152 5103 5089>,
			<6027 5831 5384 5150 5105 5091>,
			<6026 5818 5400 5164 5110 5096>,
			<6023 5787 5424 5182 5116 5100>,
			<6019 5754 5418 5182 5118 5102>,
			<6012 5711 5373 5170 5118 5103>,
			<6009 5689 5337 5157 5117 5103>,
			<6018 5687 5317 5136 5101 5092>,
			<6035 5686 5305 5121 5085 5078>,
			<6053 5691 5301 5119 5083 5076>,
			<6075 5715 5298 5118 5082 5076>,
			<6098 5741 5296 5118 5082 5076>,
			<6121 5767 5292 5120 5084 5076>,
			<6147 5796 5290 5121 5086 5077>,
			<6175 5830 5294 5123 5087 5079>,
			<6208 5868 5304 5125 5089 5082>,
			<6242 5908 5316 5125 5092 5085>,
			<6279 5953 5329 5125 5096 5089>,
			<6317 6000 5346 5125 5098 5092>,
			<6355 6049 5368 5126 5092 5086>,
			<6395 6100 5393 5128 5084 5077>,
			<6437 6155 5419 5127 5083 5076>,
			<6482 6213 5446 5126 5083 5075>,
			<6530 6274 5473 5126 5083 5075>,
			<6579 6337 5497 5130 5088 5082>,
			<6633 6402 5524 5135 5091 5086>,
			<6693 6471 5558 5140 5091 5086>,
			<6780 6556 5599 5143 5090 5081>,
			<6840 6579 5592 5136 5083 5075>,
			<6967 6701 5658 5148 5090 5083>,
			<7052 6778 5701 5154 5097 5092>,
			<7150 6859 5748 5162 5108 5105>,
			<7267 6950 5800 5178 5122 5120>,
			<7398 7040 5866 5192 5129 5116>,
			<7532 7128 5925 5181 5103 5093>,
			<7692 7214 5991 5180 5104 5094>,
			<8097 7346 6122 5203 5115 5100>,
			<9086 7707 6314 5237 5134 5122>,
			<9086 7707 6314 5237 5134 5122>,
			<9086 7707 6314 5237 5134 5122>;
	};

};
